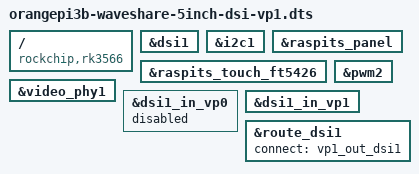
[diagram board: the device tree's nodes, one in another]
/dts-v1/;
/plugin/;

/ {
	compatible = "rockchip,rk3566";

	fragment@0 {
		target = <&dsi1>;
		__overlay__ {
			status = "okay";
		};
	};

	fragment@1 {
		target = <&i2c1>;
		__overlay__ {
			status = "okay";
		};
	};

	fragment@2 {
		target = <&raspits_panel>;
		__overlay__ {
			status = "okay";
		};
	};

	fragment@3 {
		target = <&raspits_touch_ft5426>;
		__overlay__ {
			status = "okay";
		};
	};

	fragment@4 {
		target = <&video_phy1>;
		__overlay__ {
			status = "okay";
		};
	};

	fragment@5 {
		target = <&pwm2>;
		__overlay__ {
			status = "okay";
		};
	};

	fragment@6 {
		target = <&dsi1_in_vp0>;
		__overlay__ {
			status = "disabled";
		};
	};

	fragment@7 {
		target = <&dsi1_in_vp1>;
		__overlay__ {
			status = "okay";
		};
	};

	fragment@8 {
		target = <&route_dsi1>;
		__overlay__ {
			status = "okay";
			connect = <&vp1_out_dsi1>;
		};
	};
};
